# PIC32MK0512MCJ064 register map
Vendor: Microchip
Registers are 32-bit, read-write, reset 0x0 unless marked. A register's access mark holds for its fields unless they carry their own. Addresses are absolute, and some are shared; only a register's first bit layout is shown; [hi:lo] are bit positions; {n}, {i} and the like mark numbered series.

## INT
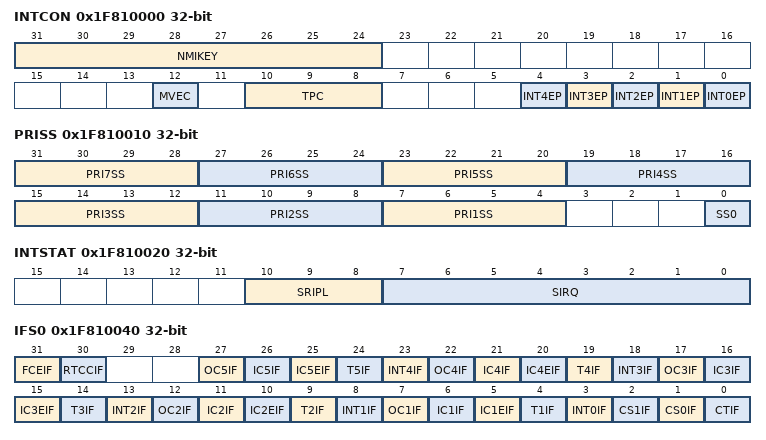
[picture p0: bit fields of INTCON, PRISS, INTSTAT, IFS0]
0x1F810000 INTCON reset not defined — (power-on value xxxxxxxx---------x-0-000---00000)
  [31:24] NMIKEY, [12] MVEC, [10:8] TPC, [n] INT{n}EP (n=0..4)
0x1F810010 PRISS
  [4n+3:4n] PRI{n}SS (n=1..7), [0] SS0
0x1F810020 INTSTAT ro
  [10:8] SRIPL, [7:0] SIRQ
0x1F810030 IPTMR
0x1F810040 IFS0
  [31] FCEIF, [30] RTCCIF, [5n+2] OC{n}IF (n=1..5), [5n+1] IC{n}IF (n=1..5), [5n] IC{n}EIF (n=1..5), [5n-1] T{n}IF (n=1..5), [5n+3] INT{n}IF (n=0..4), [2] CS1IF, [1] CS0IF, [0] CTIF
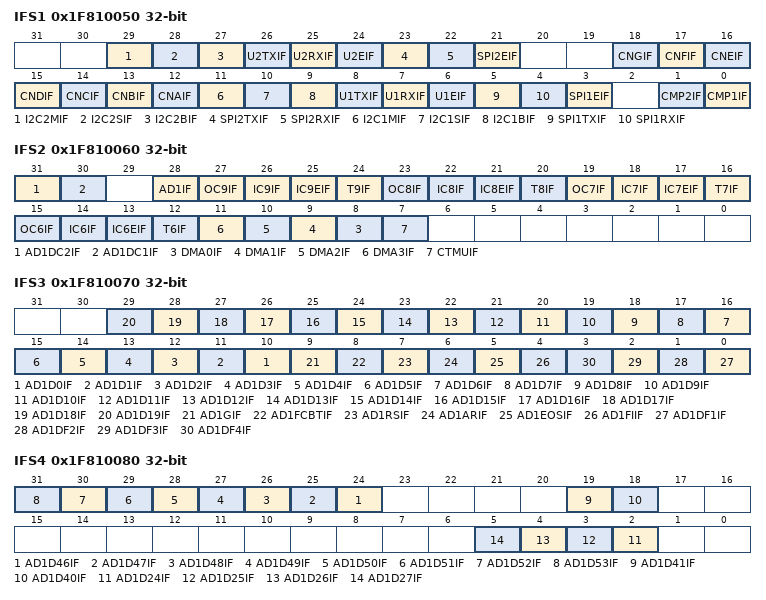
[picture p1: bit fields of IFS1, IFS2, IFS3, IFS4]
0x1F810050 IFS1
  [29] I2C2MIF, [28] I2C2SIF, [27] I2C2BIF, [26] U2TXIF, [25] U2RXIF, [24] U2EIF, [23] SPI2TXIF, [22] SPI2RXIF, [21] SPI2EIF, [18] CNGIF, [17] CNFIF, [16] CNEIF, [15] CNDIF, [14] CNCIF, [13] CNBIF, [12] CNAIF, [11] I2C1MIF, [10] I2C1SIF, [9] I2C1BIF, [8] U1TXIF, [7] U1RXIF, [6] U1EIF, [5] SPI1TXIF, [4] SPI1RXIF, [3] SPI1EIF, [1] CMP2IF, [0] CMP1IF
0x1F810060 IFS2 reset not defined — (power-on value 0x-0000000000000000000000-------)
  [31] AD1DC2IF, [30] AD1DC1IF, [28] AD1IF, [4n-9] OC{n}IF (n=6..9), [4n-10] IC{n}IF (n=6..9), [4n-11] IC{n}EIF (n=6..9), [4n-12] T{n}IF (n=6..9), [n+8] DMA{n}IF (n=0..3), [7] CTMUIF
0x1F810070 IFS3 reset not defined — (power-on value --00000000000000000x0000x0000000)
  [n+10] AD1D{n}IF (n=0..19), [9] AD1GIF, [8] AD1FCBTIF, [7] AD1RSIF, [6] AD1ARIF, [5] AD1EOSIF, [4] AD1FIIF, [n-1] AD1DF{n}IF (n=1..4)
0x1F810080 IFS4
  [n-22] AD1D{n}IF (n=46..53), [19] AD1D41IF, [18] AD1D40IF, [n-22] AD1D{n}IF (n=24..27)
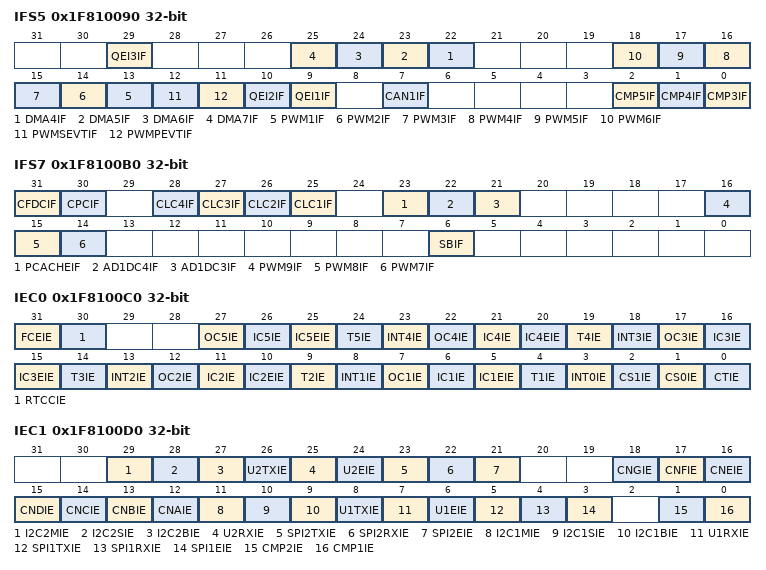
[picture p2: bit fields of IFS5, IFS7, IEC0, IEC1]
0x1F810090 IFS5 reset not defined — (power-on value --x---0000---xxxxxxxxxx-0----000)
  [29] QEI3IF, [n+18] DMA{n}IF (n=4..7), [n+12] PWM{n}IF (n=1..6), [12] PWMSEVTIF, [11] PWMPEVTIF, [10] QEI2IF, [9] QEI1IF, [7] CAN1IF, [2] CMP5IF, [1] CMP4IF, [0] CMP3IF
0x1F8100B0 IFS7 reset not defined — (power-on value xx-xxxx-xxx----xxx-------x------)
  [31] CFDCIF
  [30] CPCIF
  [n+24] CLC{n}IF (n=1..4)
  [23] PCACHEIF — PCACHE Interrupt Flag
  [22] AD1DC4IF
  [21] AD1DC3IF
  [16] PWM9IF
  [15] PWM8IF
  [14] PWM7IF
  [6] SBIF
0x1F8100C0 IEC0
  [31] FCEIE, [30] RTCCIE, [5n+2] OC{n}IE (n=1..5), [5n+1] IC{n}IE (n=1..5), [5n] IC{n}EIE (n=1..5), [5n-1] T{n}IE (n=1..5), [5n+3] INT{n}IE (n=0..4), [2] CS1IE, [1] CS0IE, [0] CTIE
0x1F8100D0 IEC1
  [29] I2C2MIE, [28] I2C2SIE, [27] I2C2BIE, [26] U2TXIE, [25] U2RXIE, [24] U2EIE, [23] SPI2TXIE, [22] SPI2RXIE, [21] SPI2EIE, [18] CNGIE, [17] CNFIE, [16] CNEIE, [15] CNDIE, [14] CNCIE, [13] CNBIE, [12] CNAIE, [11] I2C1MIE, [10] I2C1SIE, [9] I2C1BIE, [8] U1TXIE, [7] U1RXIE, [6] U1EIE, [5] SPI1TXIE, [4] SPI1RXIE, [3] SPI1EIE, [1] CMP2IE, [0] CMP1IE
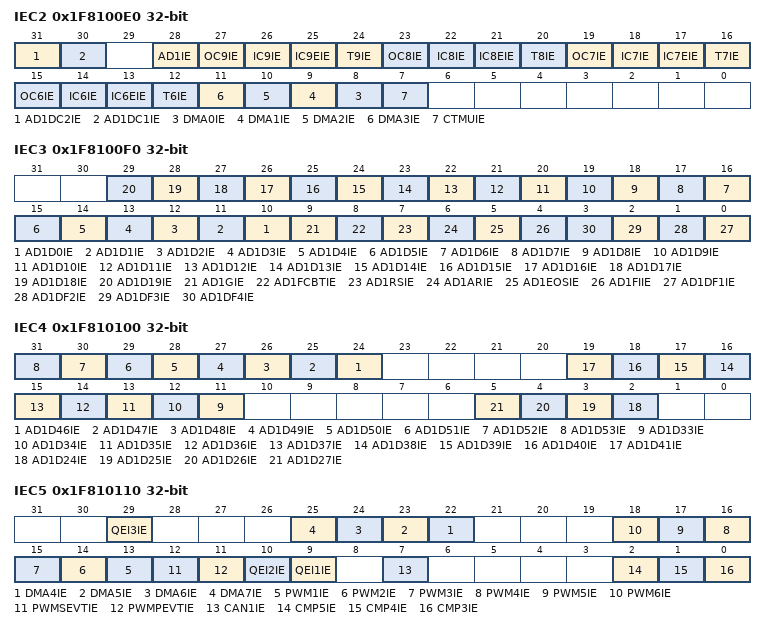
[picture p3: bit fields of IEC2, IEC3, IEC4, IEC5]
0x1F8100E0 IEC2 reset not defined — (power-on value 0x-0000000000000000000000-------)
  [31] AD1DC2IE, [30] AD1DC1IE, [28] AD1IE, [4n-9] OC{n}IE (n=6..9), [4n-10] IC{n}IE (n=6..9), [4n-11] IC{n}EIE (n=6..9), [4n-12] T{n}IE (n=6..9), [n+8] DMA{n}IE (n=0..3), [7] CTMUIE
0x1F8100F0 IEC3 reset not defined — (power-on value --00000000000000000x0000x0000000)
  [n+10] AD1D{n}IE (n=0..19), [9] AD1GIE, [8] AD1FCBTIE, [7] AD1RSIE, [6] AD1ARIE, [5] AD1EOSIE, [4] AD1FIIE, [n-1] AD1DF{n}IE (n=1..4)
0x1F810100 IEC4
  [n-22] AD1D{n}IE (n=46..53), [n-22] AD1D{n}IE (n=33..41), [n-22] AD1D{n}IE (n=24..27)
0x1F810110 IEC5 reset not defined — (power-on value --x---0000---xxxxxxxxxx-0----000)
  [29] QEI3IE, [n+18] DMA{n}IE (n=4..7), [n+12] PWM{n}IE (n=1..6), [12] PWMSEVTIE, [11] PWMPEVTIE, [10] QEI2IE, [9] QEI1IE, [7] CAN1IE, [2] CMP5IE, [1] CMP4IE, [0] CMP3IE
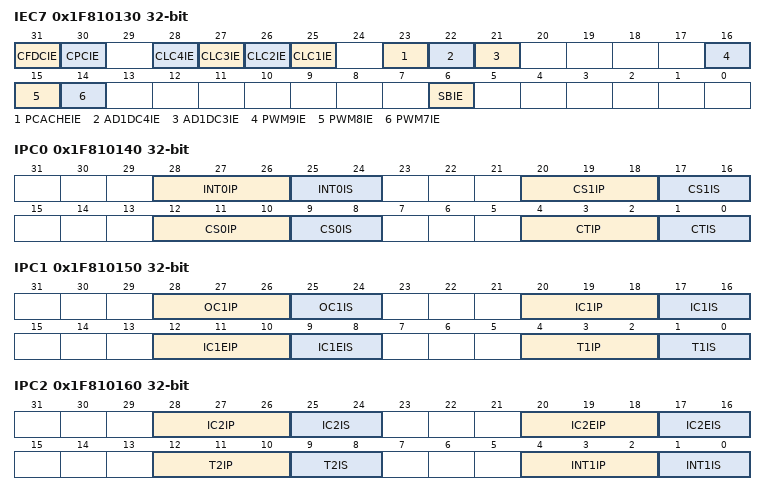
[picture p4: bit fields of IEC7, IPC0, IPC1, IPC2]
0x1F810130 IEC7 reset not defined — (power-on value xx-xxxx-xxx----xxx-------x------)
  [31] CFDCIE
  [30] CPCIE
  [n+24] CLC{n}IE (n=1..4)
  [23] PCACHEIE — PCACHE Interrupt Enable
  [22] AD1DC4IE
  [21] AD1DC3IE
  [16] PWM9IE
  [15] PWM8IE
  [14] PWM7IE
  [6] SBIE
0x1F810140 IPC0
  [28:26] INT0IP, [25:24] INT0IS, [20:18] CS1IP, [17:16] CS1IS, [12:10] CS0IP, [9:8] CS0IS, [4:2] CTIP, [1:0] CTIS
0x1F810150 IPC1
  [28:26] OC1IP, [25:24] OC1IS, [20:18] IC1IP, [17:16] IC1IS, [12:10] IC1EIP, [9:8] IC1EIS, [4:2] T1IP, [1:0] T1IS
0x1F810160 IPC2
  [28:26] IC2IP, [25:24] IC2IS, [20:18] IC2EIP, [17:16] IC2EIS, [12:10] T2IP, [9:8] T2IS, [4:2] INT1IP, [1:0] INT1IS
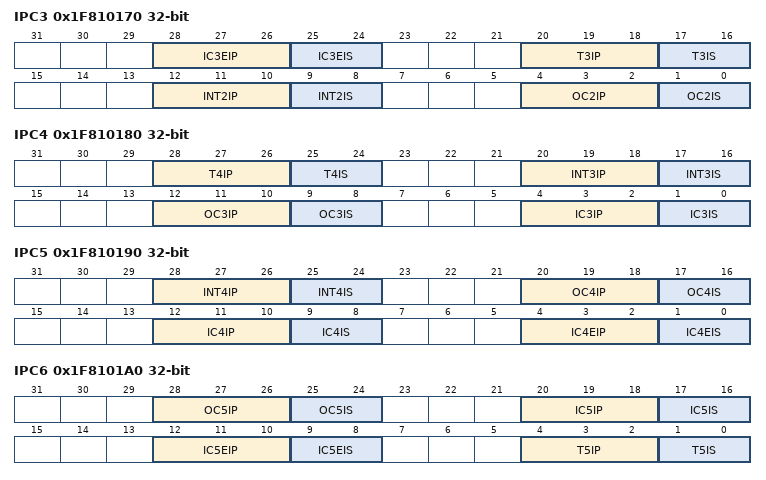
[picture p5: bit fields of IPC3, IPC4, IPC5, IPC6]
0x1F810170 IPC3
  [28:26] IC3EIP, [25:24] IC3EIS, [20:18] T3IP, [17:16] T3IS, [12:10] INT2IP, [9:8] INT2IS, [4:2] OC2IP, [1:0] OC2IS
0x1F810180 IPC4
  [28:26] T4IP, [25:24] T4IS, [20:18] INT3IP, [17:16] INT3IS, [12:10] OC3IP, [9:8] OC3IS, [4:2] IC3IP, [1:0] IC3IS
0x1F810190 IPC5
  [28:26] INT4IP, [25:24] INT4IS, [20:18] OC4IP, [17:16] OC4IS, [12:10] IC4IP, [9:8] IC4IS, [4:2] IC4EIP, [1:0] IC4EIS
0x1F8101A0 IPC6
  [28:26] OC5IP, [25:24] OC5IS, [20:18] IC5IP, [17:16] IC5IS, [12:10] IC5EIP, [9:8] IC5EIS, [4:2] T5IP, [1:0] T5IS
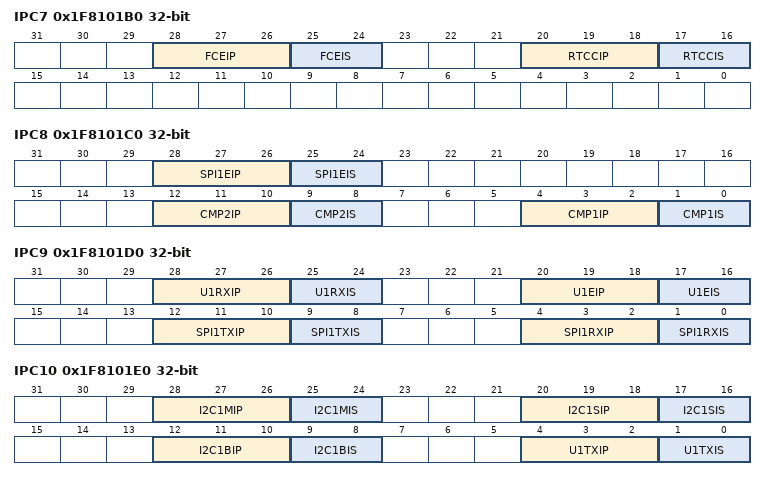
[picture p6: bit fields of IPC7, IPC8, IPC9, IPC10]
0x1F8101B0 IPC7
  [28:26] FCEIP, [25:24] FCEIS, [20:18] RTCCIP, [17:16] RTCCIS
0x1F8101C0 IPC8
  [28:26] SPI1EIP, [25:24] SPI1EIS, [12:10] CMP2IP, [9:8] CMP2IS, [4:2] CMP1IP, [1:0] CMP1IS
0x1F8101D0 IPC9
  [28:26] U1RXIP, [25:24] U1RXIS, [20:18] U1EIP, [17:16] U1EIS, [12:10] SPI1TXIP, [9:8] SPI1TXIS, [4:2] SPI1RXIP, [1:0] SPI1RXIS
0x1F8101E0 IPC10
  [28:26] I2C1MIP, [25:24] I2C1MIS, [20:18] I2C1SIP, [17:16] I2C1SIS, [12:10] I2C1BIP, [9:8] I2C1BIS, [4:2] U1TXIP, [1:0] U1TXIS
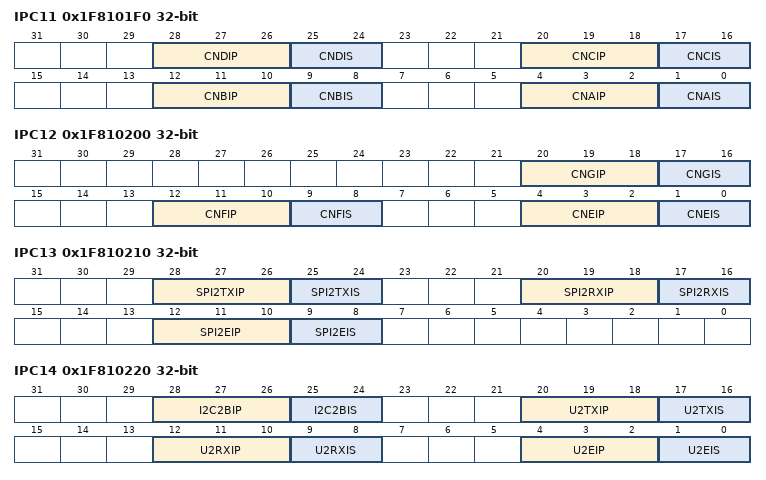
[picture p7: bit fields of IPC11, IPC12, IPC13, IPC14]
0x1F8101F0 IPC11
  [28:26] CNDIP, [25:24] CNDIS, [20:18] CNCIP, [17:16] CNCIS, [12:10] CNBIP, [9:8] CNBIS, [4:2] CNAIP, [1:0] CNAIS
0x1F810200 IPC12
  [20:18] CNGIP, [17:16] CNGIS, [12:10] CNFIP, [9:8] CNFIS, [4:2] CNEIP, [1:0] CNEIS
0x1F810210 IPC13
  [28:26] SPI2TXIP, [25:24] SPI2TXIS, [20:18] SPI2RXIP, [17:16] SPI2RXIS, [12:10] SPI2EIP, [9:8] SPI2EIS
0x1F810220 IPC14
  [28:26] I2C2BIP, [25:24] I2C2BIS, [20:18] U2TXIP, [17:16] U2TXIS, [12:10] U2RXIP, [9:8] U2RXIS, [4:2] U2EIP, [1:0] U2EIS
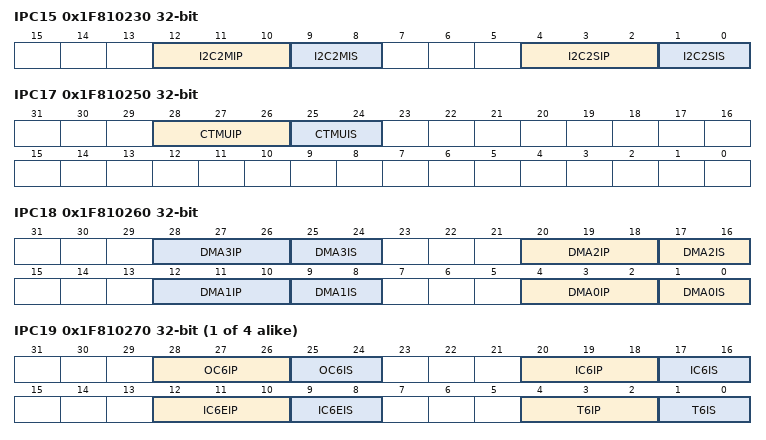
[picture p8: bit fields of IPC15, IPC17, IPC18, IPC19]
0x1F810230 IPC15
  [12:10] I2C2MIP, [9:8] I2C2MIS, [4:2] I2C2SIP, [1:0] I2C2SIS
0x1F810250 IPC17
  [28:26] CTMUIP, [25:24] CTMUIS
0x1F810260 IPC18
  [8n+4:8n+2] DMA{n}IP (n=0..3), [8n+1:8n] DMA{n}IS (n=0..3)
{0x1F810140+0x10*i} IPC{i} (i=19..22)
  [28:26] OC{i-13}IP, [25:24] OC{i-13}IS, [20:18] IC{i-13}IP, [17:16] IC{i-13}IS, [12:10] IC{i-13}EIP, [9:8] IC{i-13}EIS, [4:2] T{i-13}IP, [1:0] T{i-13}IS
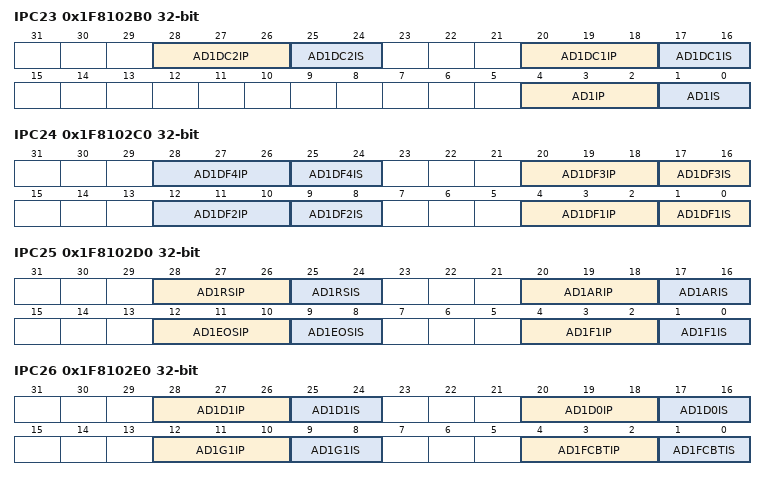
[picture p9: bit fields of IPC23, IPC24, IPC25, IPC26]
0x1F8102B0 IPC23
  [28:26] AD1DC2IP, [25:24] AD1DC2IS, [20:18] AD1DC1IP, [17:16] AD1DC1IS, [4:2] AD1IP, [1:0] AD1IS
0x1F8102C0 IPC24
  [8n-4:8n-6] AD1DF{n}IP (n=1..4), [8n-7:8n-8] AD1DF{n}IS (n=1..4)
0x1F8102D0 IPC25
  [28:26] AD1RSIP, [25:24] AD1RSIS, [20:18] AD1ARIP, [17:16] AD1ARIS, [12:10] AD1EOSIP, [9:8] AD1EOSIS, [4:2] AD1F1IP, [1:0] AD1F1IS
0x1F8102E0 IPC26
  [28:26] AD1D1IP, [25:24] AD1D1IS, [20:18] AD1D0IP, [17:16] AD1D0IS, [12:10] AD1G1IP, [9:8] AD1G1IS, [4:2] AD1FCBTIP, [1:0] AD1FCBTIS
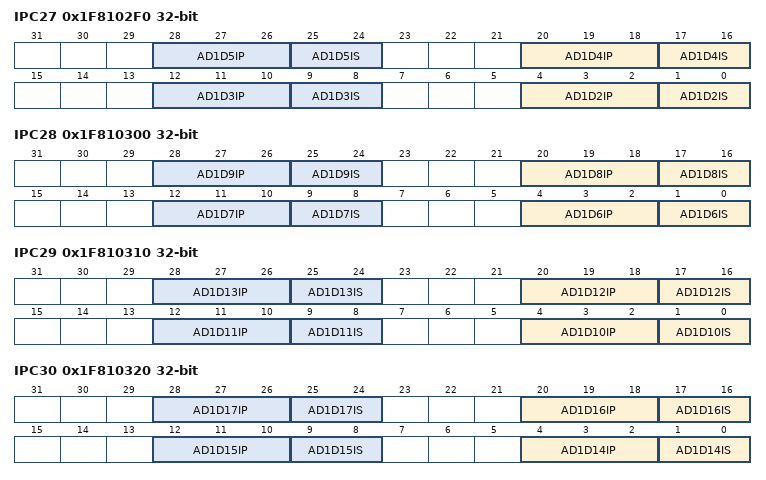
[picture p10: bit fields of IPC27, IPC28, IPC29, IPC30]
0x1F8102F0 IPC27
  [8n-12:8n-14] AD1D{n}IP (n=2..5), [8n-15:8n-16] AD1D{n}IS (n=2..5)
0x1F810300 IPC28
  [8n-44:8n-46] AD1D{n}IP (n=6..9), [8n-47:8n-48] AD1D{n}IS (n=6..9)
0x1F810310 IPC29
  [8n-76:8n-78] AD1D{n}IP (n=10..13), [8n-79:8n-80] AD1D{n}IS (n=10..13)
0x1F810320 IPC30
  [8n-108:8n-110] AD1D{n}IP (n=14..17), [8n-111:8n-112] AD1D{n}IS (n=14..17)
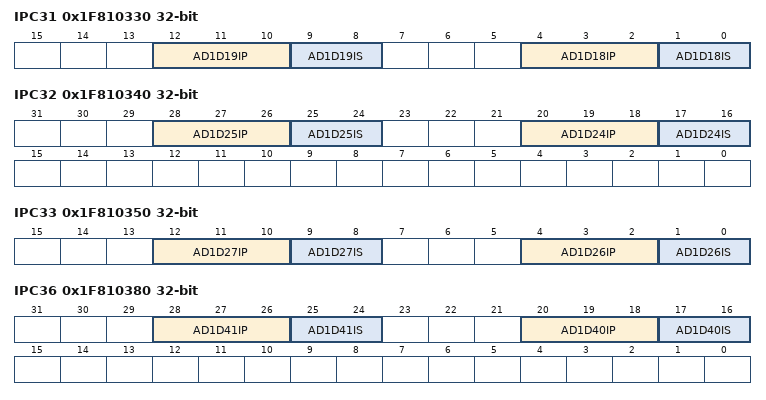
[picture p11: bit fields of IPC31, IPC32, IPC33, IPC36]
0x1F810330 IPC31
  [12:10] AD1D19IP, [9:8] AD1D19IS, [4:2] AD1D18IP, [1:0] AD1D18IS
0x1F810340 IPC32
  [28:26] AD1D25IP, [25:24] AD1D25IS, [20:18] AD1D24IP, [17:16] AD1D24IS
0x1F810350 IPC33
  [12:10] AD1D27IP, [9:8] AD1D27IS, [4:2] AD1D26IP, [1:0] AD1D26IS
0x1F810360 IPC34 access not given reset not defined
0x1F810380 IPC36
  [28:26] AD1D41IP, [25:24] AD1D41IS, [20:18] AD1D40IP, [17:16] AD1D40IS
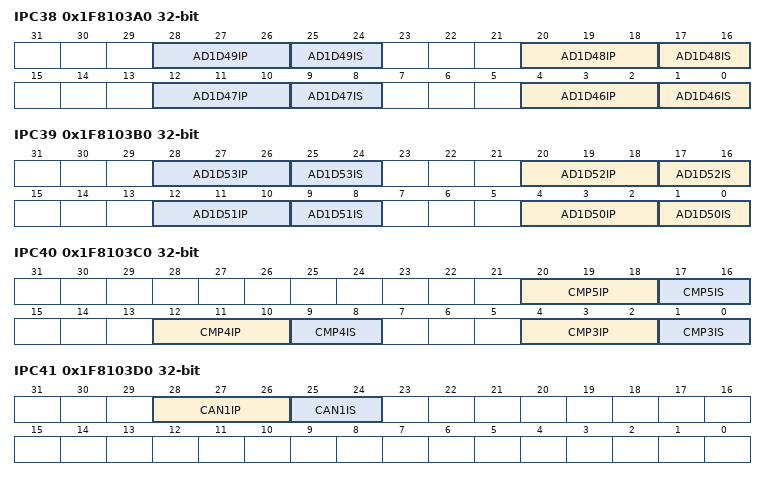
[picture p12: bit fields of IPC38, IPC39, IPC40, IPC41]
0x1F8103A0 IPC38
  [8n-364:8n-366] AD1D{n}IP (n=46..49), [8n-367:8n-368] AD1D{n}IS (n=46..49)
0x1F8103B0 IPC39
  [8n-396:8n-398] AD1D{n}IP (n=50..53), [8n-399:8n-400] AD1D{n}IS (n=50..53)
0x1F8103C0 IPC40
  [20:18] CMP5IP, [17:16] CMP5IS, [12:10] CMP4IP, [9:8] CMP4IS, [4:2] CMP3IP, [1:0] CMP3IS
0x1F8103D0 IPC41
  [28:26] CAN1IP, [25:24] CAN1IS
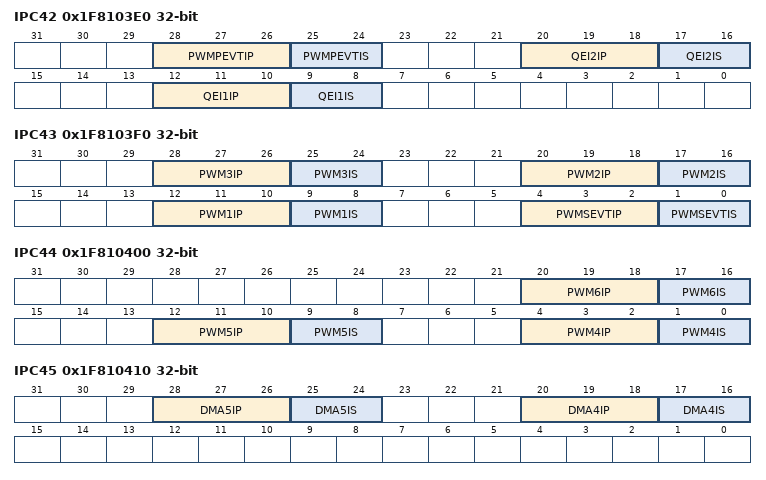
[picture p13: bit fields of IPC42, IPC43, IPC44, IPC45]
0x1F8103E0 IPC42 reset not defined — (power-on value ---xxxxx---xxxxx---xxxxx--------)
  [28:26] PWMPEVTIP, [25:24] PWMPEVTIS, [20:18] QEI2IP, [17:16] QEI2IS, [12:10] QEI1IP, [9:8] QEI1IS
0x1F8103F0 IPC43 reset not defined — (power-on value -----------xxxxx---xxxxx---xxxxx)
  [28:26] PWM3IP, [25:24] PWM3IS, [20:18] PWM2IP, [17:16] PWM2IS, [12:10] PWM1IP, [9:8] PWM1IS, [4:2] PWMSEVTIP, [1:0] PWMSEVTIS
0x1F810400 IPC44 access not given reset not defined
  [20:18] PWM6IP, [17:16] PWM6IS, [12:10] PWM5IP, [9:8] PWM5IS, [4:2] PWM4IP, [1:0] PWM4IS
0x1F810410 IPC45
  [28:26] DMA5IP, [25:24] DMA5IS, [20:18] DMA4IP, [17:16] DMA4IS
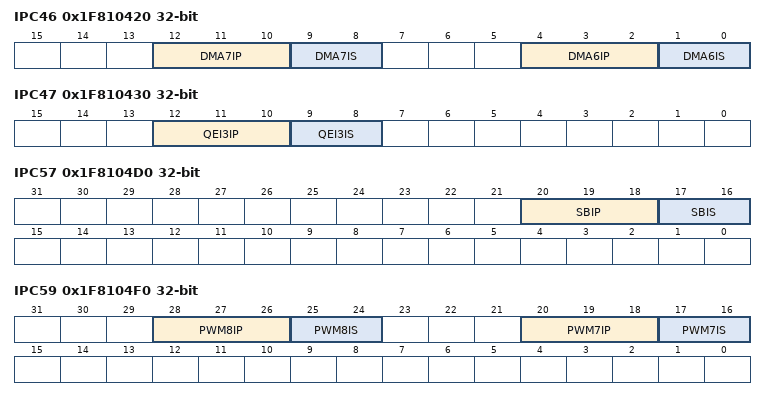
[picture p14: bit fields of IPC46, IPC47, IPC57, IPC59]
0x1F810420 IPC46
  [12:10] DMA7IP, [9:8] DMA7IS, [4:2] DMA6IP, [1:0] DMA6IS
0x1F810430 IPC47 reset not defined — (power-on value -------------------xxxxx--------)
  [12:10] QEI3IP, [9:8] QEI3IS
0x1F8104D0 IPC57
  [20:18] SBIP, [17:16] SBIS
0x1F8104F0 IPC59 reset not defined — (power-on value ---xxxxx---xxxxx----------------)
  [28:26] PWM8IP, [25:24] PWM8IS, [20:18] PWM7IP, [17:16] PWM7IS
0x1F810500 IPC60 reset not defined — (power-on value ---------------------------xxxxx)
  [4:2] PWM9IP, [1:0] PWM9IS
0x1F810510 IPC61 reset not defined — (power-on value ---xxxxx---00000---00000--------)
  [28:26] PCACHEIP — PCACHE Interrupt Priority
  [25:24] PCACHEIS — PCACHE Interrupt Sub-Priority
  [20:18] AD1DC4IP
  [17:16] AD1DC4IS
  [12:10] AD1DC3IP
  [9:8] AD1DC3IS
0x1F810520 IPC62 reset not defined — (power-on value ---xxxxx---xxxxx---xxxxx--------)
  [28:26] CLC3IP, [25:24] CLC3IS, [20:18] CLC2IP, [17:16] CLC2IS, [12:10] CLC1IP, [9:8] CLC1IS
0x1F810530 IPC63 reset not defined — (power-on value ---xxxxx---00000-----------xxxxx)
  [28:26] CFDCIP, [25:24] CFDCIS, [20:18] CPCIP, [17:16] CPCIS, [4:2] CLC4IP, [1:0] CLC4IS
{0x1F810540+4i} OFF{i:03} (i=0..27)
  [17:1] VOFF
{0x1F810540+4i} OFF{i:03} (i=30..33)
  [17:1] VOFF
{0x1F810540+4i} OFF{i:03} (i=35..50)
  [17:1] VOFF
{0x1F810540+4i} OFF{i:03} (i=53..61)
  [17:1] VOFF
{0x1F810540+4i} OFF{i:03} (i=71..92)
  [17:1] VOFF
{0x1F810540+4i} OFF{i:03} (i=94..125)
  [17:1] VOFF
{0x1F810540+4i} OFF{i} (i=130..133)
  [17:1] VOFF
0x1F810788 OFF146
  [17:1] VOFF
0x1F81078C OFF147
  [17:1] VOFF
{0x1F810540+4i} OFF{i} (i=152..162)
  [17:1] VOFF
0x1F8107DC OFF167
  [17:1] VOFF
{0x1F810540+4i} OFF{i} (i=169..178)
  [17:1] VOFF
{0x1F810540+4i} OFF{i} (i=182..185)
  [17:1] VOFF
0x1F810834 OFF189 access not given reset not defined
0x1F8108D8 OFF230
  [17:1] VOFF
{0x1F810540+4i} OFF{i} (i=238..240)
  [17:1] VOFF
{0x1F810540+4i} OFF{i} (i=245..247)
  [17:1] VOFF
{0x1F810540+4i} OFF{i} (i=249..252)
  [17:1] VOFF
0x1F810938 OFF254
  [17:1] VOFF
0x1F81093C OFF255
  [17:1] VOFF
